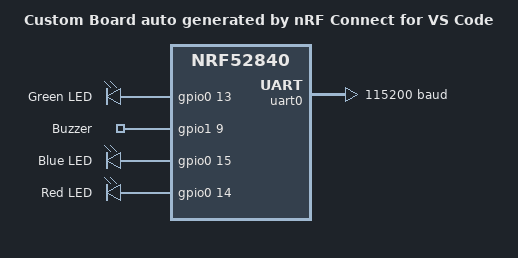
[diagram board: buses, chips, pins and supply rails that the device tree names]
/dts-v1/;
#include <nordic/nrf52840_qiaa.dtsi>
#include <nordic/nrf52840_partition.dtsi>
#include "RPT00061-pinctrl.dtsi"

/ {
	model = "Custom Board auto generated by nRF Connect for VS Code";
	compatible = "Noke,RPT00061";

	chosen {
		zephyr,console = &uart0;
		zephyr,shell-uart = &uart0;
		zephyr,uart-mcumgr = &uart0;
		zephyr,bt-mon-uart = &uart0;
		zephyr,bt-c2h-uart = &uart0;
		zephyr,ieee802154 = &ieee802154;
	};

	leds {
		compatible = "gpio-leds";
		led0: led_0 {
			gpios = <&gpio0 13 GPIO_ACTIVE_HIGH>;
			label = "Green LED";
		};
		led1: led_1 {
			gpios = <&gpio1 9 GPIO_ACTIVE_HIGH>;
			label = "Buzzer";
		};
		led2: led_2 {
			gpios = <&gpio0 15 GPIO_ACTIVE_HIGH>;
			label = "Blue LED";
		};
		led3: led_3 {
			gpios = <&gpio0 14 GPIO_ACTIVE_HIGH>;
			label = "Red LED";
		};
	};

	aliases {
		led0 = &led0;
		led1 = &led1;
		led2 = &led2;
		led3 = &led3;
	};

};

&gpiote {
	status = "okay";
};

&gpio0 {
	status = "okay";
};

&gpio1 {
	status = "okay";
};

&uart0 {
	compatible = "nordic,nrf-uarte";
	status = "okay";
	current-speed = <115200>;
	pinctrl-0 = <&uart0_default>;
	pinctrl-1 = <&uart0_sleep>;
	pinctrl-names = "default", "sleep";
};

&reg0 {
	status = "disabled";
};

&reg1 {
	regulator-initial-mode = <NRF5X_REG_MODE_DCDC>;
};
